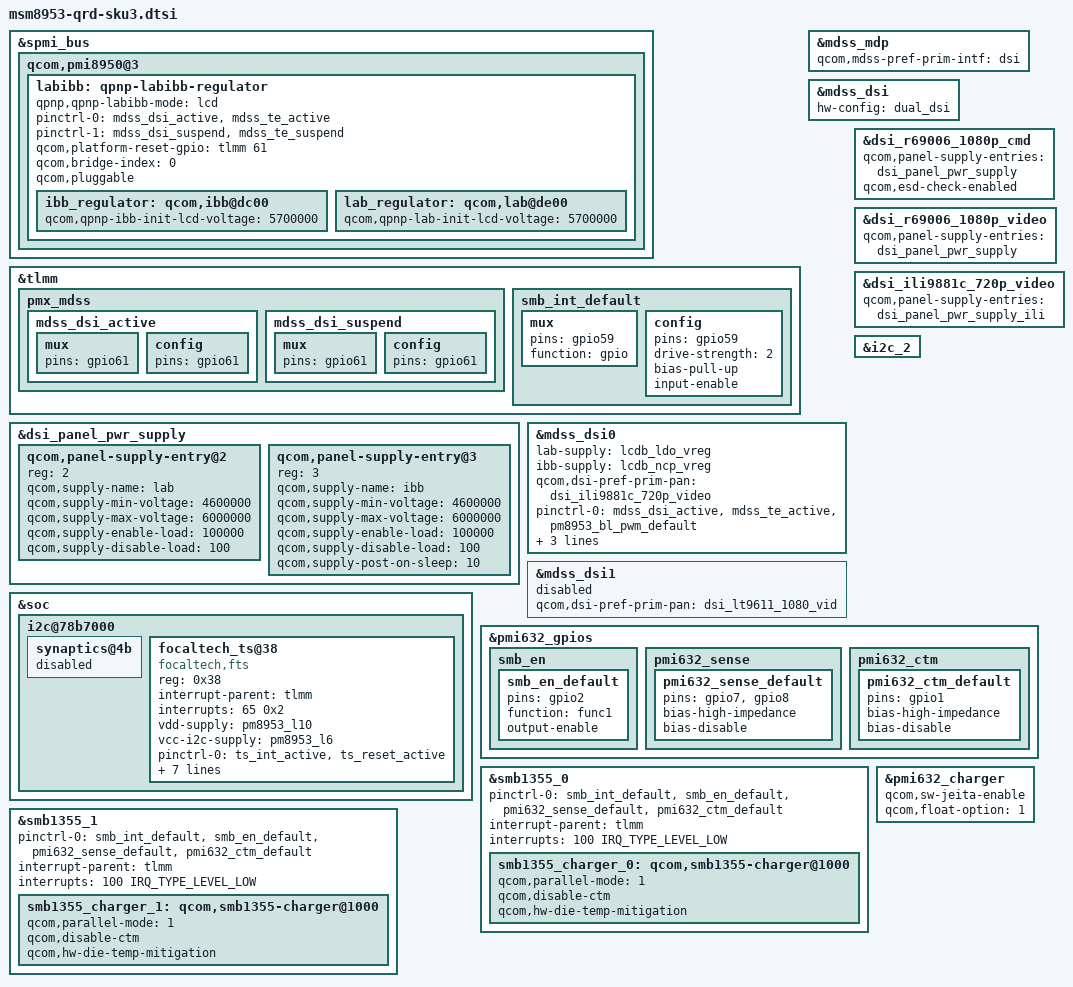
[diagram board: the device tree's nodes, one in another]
/*
 * Copyright (c) 2015-2017, 2019 The Linux Foundation. All rights reserved.
 *
 * This program is free software; you can redistribute it and/or modify
 * it under the terms of the GNU General Public License version 2 and
 * only version 2 as published by the Free Software Foundation.
 *
 * This program is distributed in the hope that it will be useful,
 * but WITHOUT ANY WARRANTY; without even the implied warranty of
 * MERCHANTABILITY or FITNESS FOR A PARTICULAR PURPOSE.  See the
 * GNU General Public License for more details.
 */

#include "msm8953-qrd.dtsi"
#include "msm8953-camera-sensor-qrd.dtsi"

&spmi_bus {
	qcom,pmi8950@3 {
		labibb: qpnp-labibb-regulator {
			ibb_regulator: qcom,ibb@dc00 {
				/delete-property/
					qcom,qpnp-ibb-use-default-voltage;
				qcom,qpnp-ibb-init-lcd-voltage = <5700000>;
			};

			lab_regulator: qcom,lab@de00 {
				/delete-property/
					qcom,qpnp-lab-use-default-voltage;
				qcom,qpnp-lab-init-lcd-voltage = <5700000>;
			};
		};
	};
};

#include "msm8953-mdss-panels.dtsi"

&tlmm {
	pmx_mdss {
		mdss_dsi_active: mdss_dsi_active {
			mux {
				pins = "gpio61";
			};
			config {
				pins = "gpio61";
			};
		};
		mdss_dsi_suspend: mdss_dsi_suspend {
			mux {
				pins = "gpio61";
			};
			config {
				pins = "gpio61";
			};
		};
	};
};

&dsi_panel_pwr_supply {
		qcom,panel-supply-entry@2 {
		reg = <2>;
		qcom,supply-name = "lab";
		qcom,supply-min-voltage = <4600000>;
		qcom,supply-max-voltage = <6000000>;
		qcom,supply-enable-load = <100000>;
		qcom,supply-disable-load = <100>;
	};

	qcom,panel-supply-entry@3 {
		reg = <3>;
		qcom,supply-name = "ibb";
		qcom,supply-min-voltage = <4600000>;
		qcom,supply-max-voltage = <6000000>;
		qcom,supply-enable-load = <100000>;
		qcom,supply-disable-load = <100>;
		qcom,supply-post-on-sleep = <10>;
	};
};

&mdss_mdp {
	qcom,mdss-pref-prim-intf = "dsi";
};

&mdss_dsi {
    hw-config = "dual_dsi";
};

&mdss_dsi0 {
	lab-supply = <&lcdb_ldo_vreg>;
	ibb-supply = <&lcdb_ncp_vreg>;

	qcom,dsi-pref-prim-pan = <&dsi_ili9881c_720p_video>;
 	pinctrl-names = "mdss_default", "mdss_sleep";
	pinctrl-0 = <&mdss_dsi_active &mdss_te_active &pm8953_bl_pwm_default>;
 	pinctrl-1 = <&mdss_dsi_suspend &mdss_te_suspend>;
 	qcom,platform-reset-gpio = <&tlmm 61 0>;
	qcom,platform-enable-gpio = <&pm8953_gpios 4 0>;
};

&mdss_dsi1 {
	status = "disabled";
	qcom,dsi-pref-prim-pan = <&dsi_lt9611_1080_vid>;
};
 
&labibb {
	status = "ok";
	qpnp,qpnp-labibb-mode = "lcd";
	pinctrl-names = "mdss_default", "mdss_sleep";
	pinctrl-0 = <&mdss_dsi_active &mdss_te_active>;
	pinctrl-1 = <&mdss_dsi_suspend &mdss_te_suspend>;
	qcom,platform-reset-gpio = <&tlmm 61 0>;
	qcom,bridge-index = <0>;
	qcom,pluggable;
};

&dsi_r69006_1080p_cmd {
	qcom,panel-supply-entries = <&dsi_panel_pwr_supply>;
	qcom,esd-check-enabled;
};

&dsi_r69006_1080p_video {
	qcom,panel-supply-entries = <&dsi_panel_pwr_supply>;
};

&dsi_ili9881c_720p_video {
	qcom,panel-supply-entries = <&dsi_panel_pwr_supply_ili>;
};

&soc {
	i2c@78b7000 { /* BLSP1 QUP3 */
		status = "ok";
		synaptics@4b {
			status = "disabled";
		};

		focaltech_ts@38 {
			compatible = "focaltech,fts";
			reg = <0x38>;
			interrupt-parent = <&tlmm>;
			interrupts = <65 0x2>;
			vdd-supply = <&pm8953_l10>;
			vcc-i2c-supply = <&pm8953_l6>;
			pinctrl-names = "pmx_ts_active","pmx_ts_suspend",
				"pmx_ts_release";
			pinctrl-0 = <&ts_int_active &ts_reset_active>;
			pinctrl-1 = <&ts_int_suspend &ts_reset_suspend>;
			pinctrl-2 = <&ts_release>;
			focaltech,display-coords = <0 0 720 1280>;
			focaltech,reset-gpio = <&tlmm 64 0x0>;
			focaltech,irq-gpio = <&tlmm 65 0x2>;
			focaltech,max-touch-number = <5>;
			report_type = <1>;
		};
	};
};

&i2c_2 {
	#address-cells = <1>;
	#size-cells = <0>;

	#include "smb1355.dtsi"
};

&pmi632_gpios {
	smb_en {
		smb_en_default: smb_en_default {
			pins = "gpio2";
			function = "func1";
			output-enable;
		};
	};

	pmi632_sense {
		/* GPIO 7 and 8 are external-sense pins for PMI632 */
		pmi632_sense_default: pmi632_sense_default {
			pins = "gpio7", "gpio8";
			bias-high-impedance;	/* disable the GPIO */
			bias-disable;		/* no-pull */
		};
	};

	pmi632_ctm {
		/* Disable GPIO1 for h/w base mitigation */
		pmi632_ctm_default: pmi632_ctm_default {
			pins = "gpio1";
			bias-high-impedance;	/* disable the GPIO */
			bias-disable;		/* no-pull */
		};
	};
};

&tlmm {
	smb_int_default: smb_int_default {
		mux {
			pins = "gpio59";
			function = "gpio";
		};
		config {
			pins = "gpio59";
			drive-strength = <2>;
			bias-pull-up;
			input-enable;
		};
	};
};

&smb1355_0 {
	pinctrl-names = "default";
	pinctrl-0 = <&smb_int_default
		&smb_en_default &pmi632_sense_default &pmi632_ctm_default>;
	interrupt-parent = <&tlmm>;
	interrupts = <100 IRQ_TYPE_LEVEL_LOW>;
	smb1355_charger_0: qcom,smb1355-charger@1000 {
		status ="ok";
		/delete-property/ io-channels;
		/delete-property/ io-channels-names;
		qcom,parallel-mode = <1>;
		qcom,disable-ctm;
		qcom,hw-die-temp-mitigation;
	};
};

&smb1355_1 {
	pinctrl-names = "default";
	pinctrl-0 = <&smb_int_default
		&smb_en_default &pmi632_sense_default &pmi632_ctm_default>;
	interrupt-parent = <&tlmm>;
	interrupts = <100 IRQ_TYPE_LEVEL_LOW>;
	smb1355_charger_1: qcom,smb1355-charger@1000 {
		status ="ok";
		/delete-property/ io-channels;
		/delete-property/ io-channels-names;
		qcom,parallel-mode = <1>;
		qcom,disable-ctm;
		qcom,hw-die-temp-mitigation;
	};
};

&pmi632_charger {
	qcom,sw-jeita-enable;
	qcom,float-option = <1>;
};
